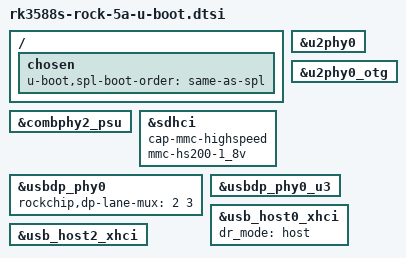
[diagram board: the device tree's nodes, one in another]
// SPDX-License-Identifier: (GPL-2.0+ OR MIT)
/*
 * Copyright (c) 2023 Collabora Ltd.
 */

#include "rk3588s-u-boot.dtsi"

/ {
	chosen {
		u-boot,spl-boot-order = "same-as-spl", &sdmmc, &sdhci;
	};
};

&combphy2_psu {
	status = "okay";
};

&sdhci {
	cap-mmc-highspeed;
	mmc-hs200-1_8v;
	/delete-property/ mmc-hs400-1_8v;
};

&u2phy0 {
	status = "okay";
};

&u2phy0_otg {
	status = "okay";
};

&usbdp_phy0 {
	status = "okay";
	rockchip,dp-lane-mux = <2 3>;
};

&usbdp_phy0_u3 {
	status = "okay";
};

&usb_host0_xhci {
	dr_mode = "host";
	status = "okay";
};

&usb_host2_xhci {
	status = "okay";
};
